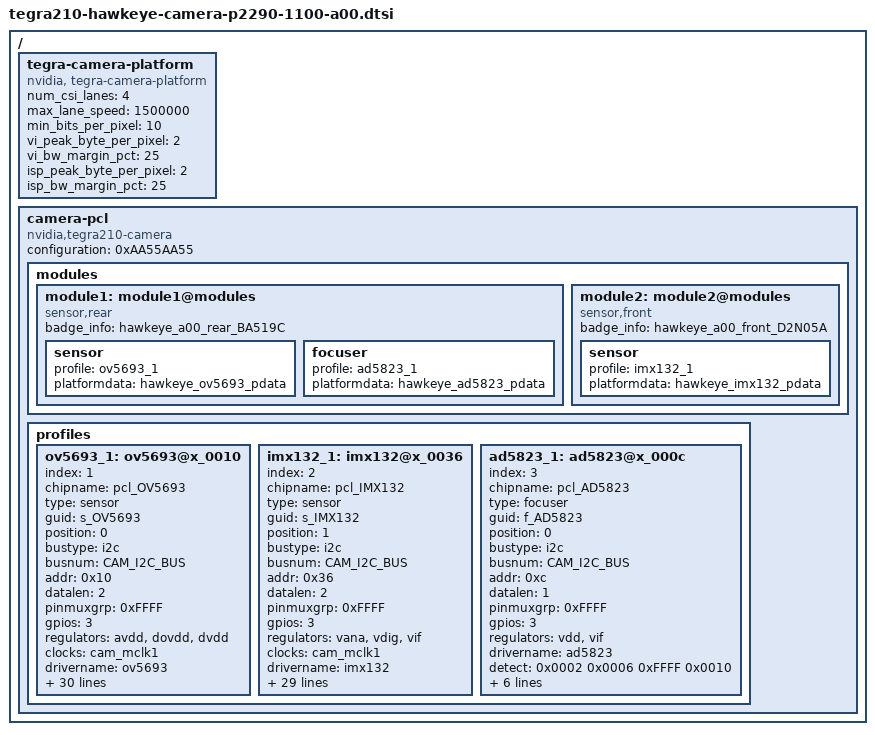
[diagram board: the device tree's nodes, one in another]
/*
 * tegra210-hawkeye-camera-p2290-1100-a00.dtsi: Hawkeye camera dtsi.
 *
 * Copyright (c) 2014-2016, NVIDIA CORPORATION.  All rights reserved.
 *
 * This program is free software; you can redistribute it and/or modify
 * it under the terms of the GNU General Public License as published by
 * the Free Software Foundation; version 2 of the License.
 *
 * This program is distributed in the hope that it will be useful, but WITHOUT
 * ANY WARRANTY; without even the implied warranty of MERCHANTABILITY or
 * FITNESS FOR A PARTICULAR PURPOSE.  See the GNU General Public License for
 * more details.
 */

#include <dt-bindings/media/camera.h>

#define CAM_I2C_BUS	6

/ {
	tegra-camera-platform {
		compatible = "nvidia, tegra-camera-platform";
		/**
		* Physical settings to calculate max ISO BW
		*
		* num_csi_lanes = <>;
		* Total number of CSI lanes when all cameras are active
		*
		* max_lane_speed = <>;
		* Max lane speed in Kbit/s
		*
		* min_bits_per_pixel = <>;
		* Min bits per pixel
		*
		* vi_peak_byte_per_pixel = <>;
		* Max byte per pixel for the VI ISO case
		*
		* vi_bw_margin_pct = <>;
		* Vi bandwidth margin in percentage
		*
		* isp_peak_byte_per_pixel = <>;
		* Max byte per pixel for the ISP ISO case
		*
		* isp_bw_margin_pct = <>;
		* Isp bandwidth margin in percentage
		*/
		num_csi_lanes = <4>;
		max_lane_speed = <1500000>;
		min_bits_per_pixel = <10>;
		vi_peak_byte_per_pixel = <2>;
		vi_bw_margin_pct = <25>;
		isp_peak_byte_per_pixel = <2>;
		isp_bw_margin_pct = <25>;
	};

	camera-pcl {
		compatible = "nvidia,tegra210-camera", "simple-bus";
		configuration = <0xAA55AA55>;

		modules {
			module1: module1@modules {
				compatible = "sensor,rear";
				badge_info = "hawkeye_a00_rear_BA519C";

				sensor {
					profile = <&ov5693_1>;
					platformdata = "hawkeye_ov5693_pdata";
				};
				focuser {
					profile = <&ad5823_1>;
					platformdata = "hawkeye_ad5823_pdata";
				};
			};
			module2: module2@modules {
				compatible = "sensor,front";
				badge_info = "hawkeye_a00_front_D2N05A";

				sensor {
					profile = <&imx132_1>;
					platformdata = "hawkeye_imx132_pdata";
				};
			};
		};

		profiles {
			ov5693_1: ov5693@x_0010 {
				index = <1>;
				chipname = "pcl_OV5693";
				type = "sensor";
				guid = "s_OV5693";
				position = <0>;
				bustype = "i2c";
				busnum = <CAM_I2C_BUS>;
				addr = <0x10>;
				datalen = <2>;
				pinmuxgrp = <0xFFFF>;
				gpios = <3>;
				regulators = "avdd", "dovdd", "dvdd";
				clocks = "cam_mclk1";
				drivername = "ov5693";
				detect = <0x0002 0x300A 0xFFFF 0x5690>;
				devid = <0x5693>;
				poweron = <
					CAMERA_IND_CLK_SET(10000)
					CAMERA_GPIO_CLR(TEGRA_GPIO(S, 7))
					CAMERA_WAITMS(1)
					CAMERA_REGULATOR_ON(0)
					CAMERA_REGULATOR_ON(2)
					CAMERA_REGULATOR_ON(1)
					CAMERA_WAITMS(1)
					CAMERA_GPIO_SET(TEGRA_GPIO(S, 7))
					CAMERA_WAITMS(10)
					CAMERA_END
					>;
				poweroff = <
					CAMERA_IND_CLK_CLR
					CAMERA_GPIO_CLR(TEGRA_GPIO(S, 7))
					CAMERA_WAITUS(10)
					CAMERA_REGULATOR_OFF(1)
					CAMERA_REGULATOR_OFF(2)
					CAMERA_REGULATOR_OFF(0)
					CAMERA_WAITMS(10)
					CAMERA_END
					>;
				/* sensor capabilities */
				cap-version = <0x34340002>;
				cap-identifier = "OV5693.0";
				cap-sensor_nvc_interface = <5>;
				cap-pixel_types = <0x2101>;
				cap-orientation = <1>;
				cap-direction = <0>;
				cap-initial_clock_rate_khz = <6000>;
				cap-h_sync_edge = <0>;
				cap-v_sync_edge = <0>;
				cap-mclk_on_vgp0 = <0>;
				cap-csi_port = <0>;
				cap-data_lanes = <2>;
				cap-virtual_channel_id = <0>;
				cap-discontinuous_clk_mode = <1>;
				cap-cil_threshold_settle = <0>;
				cap-min_blank_time_width = <16>;
				cap-min_blank_time_height = <16>;
				cap-preferred_mode_index = <0>;
				cap-external_clock_khz_0 = <24000>;
				cap-clock_multiplier_0 = <8000000>;
				cap-external_clock_khz_1 = <0>;
				cap-clock_multiplier_1 = <0>;
				cap-hdr-enabled;
				has-eeprom;
			};
			imx132_1: imx132@x_0036 {
				index = <2>;
				chipname = "pcl_IMX132";
				type = "sensor";
				guid = "s_IMX132";
				position = <1>;
				bustype = "i2c";
				busnum = <CAM_I2C_BUS>;
				addr = <0x36>;
				datalen = <2>;
				pinmuxgrp = <0xFFFF>;
				gpios = <3>;
				regulators = "vana", "vdig", "vif";
				clocks = "cam_mclk1";
				drivername = "imx132";
				detect = <0x0002 0x0000 0xFFFF 0x0132>;
				devid = <0x0132>;
				poweron = <
					CAMERA_IND_CLK_SET(10000)
					CAMERA_GPIO_CLR(TEGRA_GPIO(T, 0))
					CAMERA_GPIO_CLR(TEGRA_GPIO(S, 4))
					CAMERA_WAITMS(10)
					CAMERA_REGULATOR_ON(0)
					CAMERA_REGULATOR_ON(1)
					CAMERA_REGULATOR_ON(2)
					CAMERA_WAITMS(1)
					CAMERA_GPIO_SET(TEGRA_GPIO(T, 0))
					CAMERA_GPIO_SET(TEGRA_GPIO(S, 4))
					CAMERA_WAITMS(10)
					CAMERA_END
					>;
				poweroff = <
					CAMERA_IND_CLK_CLR
					CAMERA_GPIO_CLR(TEGRA_GPIO(T, 0))
					CAMERA_GPIO_CLR(TEGRA_GPIO(S, 4))
					CAMERA_WAITUS(10)
					CAMERA_REGULATOR_OFF(2)
					CAMERA_REGULATOR_OFF(1)
					CAMERA_REGULATOR_OFF(0)
					CAMERA_WAITMS(10)
					CAMERA_END
					>;
				/* sensor capabilities */
				cap-version = <0x34340002>;
				cap-identifier = "IMX132";
				cap-sensor_nvc_interface = <3>;
				cap-pixel_types = <0x100>;
				cap-orientation = <3>;
				cap-direction = <1>;
				cap-initial_clock_rate_khz = <6000>;
				cap-h_sync_edge = <0>;
				cap-v_sync_edge = <0>;
				cap-mclk_on_vgp0 = <0>;
				cap-csi_port = <1>;
				cap-data_lanes = <2>;
				cap-virtual_channel_id = <0>;
				cap-discontinuous_clk_mode = <1>;
				cap-cil_threshold_settle = <0>;
				cap-min_blank_time_width = <16>;
				cap-min_blank_time_height = <16>;
				cap-preferred_mode_index = <0>;
				cap-external_clock_khz_0 = <24000>;
				cap-clock_multiplier_0 = <8000000>;
				cap-external_clock_khz_1 = <0>;
				cap-clock_multiplier_1 = <0>;
				cap-hdr-enabled;
			};
			ad5823_1: ad5823@x_000c {
				index = <3>;
				chipname = "pcl_AD5823";
				type = "focuser";
				guid = "f_AD5823";
				position = <0>;
				bustype = "i2c";
				busnum = <CAM_I2C_BUS>;
				addr = <0xc>;
				datalen = <1>;
				pinmuxgrp = <0xFFFF>;
				gpios = <3>;
				regulators = "vdd", "vif";
				drivername = "ad5823";
				detect = <0x0002 0x0006 0xFFFF 0x0010>;
				devid = <0x5823>;
				poweron = <
					CAMERA_REGULATOR_ON(1)
					CAMERA_REGULATOR_ON(0)
					CAMERA_WAITUS(10)
					CAMERA_GPIO_SET(TEGRA_GPIO(S, 5))
					CAMERA_WAITUS(10)
					CAMERA_END
					>;
				poweroff = <
					CAMERA_REGULATOR_OFF(0)
					CAMERA_REGULATOR_OFF(1)
					CAMERA_GPIO_CLR(TEGRA_GPIO(S, 5))
					CAMERA_WAITMS(10)
					CAMERA_END
					>;
				support_mfi;
			};
		};
	};
};

